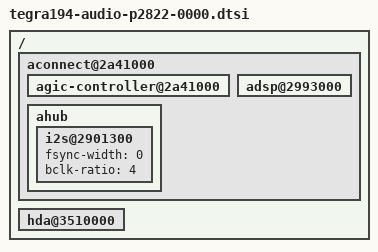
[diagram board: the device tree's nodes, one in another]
/*
 * T194 p2822-0000 audio common DTSI file.
 *
 * Copyright (c) 2017-2019, NVIDIA CORPORATION.  All rights reserved.
 *
 * This program is free software; you can redistribute it and/or modify
 * it under the terms of the GNU General Public License as published by
 * the Free Software Foundation; version 2 of the License.
 *
 * This program is distributed in the hope that it will be useful, but WITHOUT
 * ANY WARRANTY; without even the implied warranty of MERCHANTABILITY or
 * FITNESS FOR A PARTICULAR PURPOSE.  See the GNU General Public License for
 * more details.
 */

#include <audio/tegra-platforms-audio-dai-links.dtsi>
#include <dt-bindings/gpio/tegra194-gpio.h>
#include <dt-bindings/sound/rt5659.h>

/ {

	aconnect@2a41000 {
		status = "okay";

		agic-controller@2a41000 {
			status = "okay";
		};

		adsp@2993000 {
			status = "okay";
		};
	};

	/* Default for all I2S is long fsync width(31) */
	aconnect@2a41000 {
		ahub {
			/* I2S4 in Short frame sync for BT SCO */
			i2s@2901300 {
				fsync-width = <0>;
				bclk-ratio = <4>;
			};
		};
	};

	hda@3510000 {
		status = "okay";
	};
};
